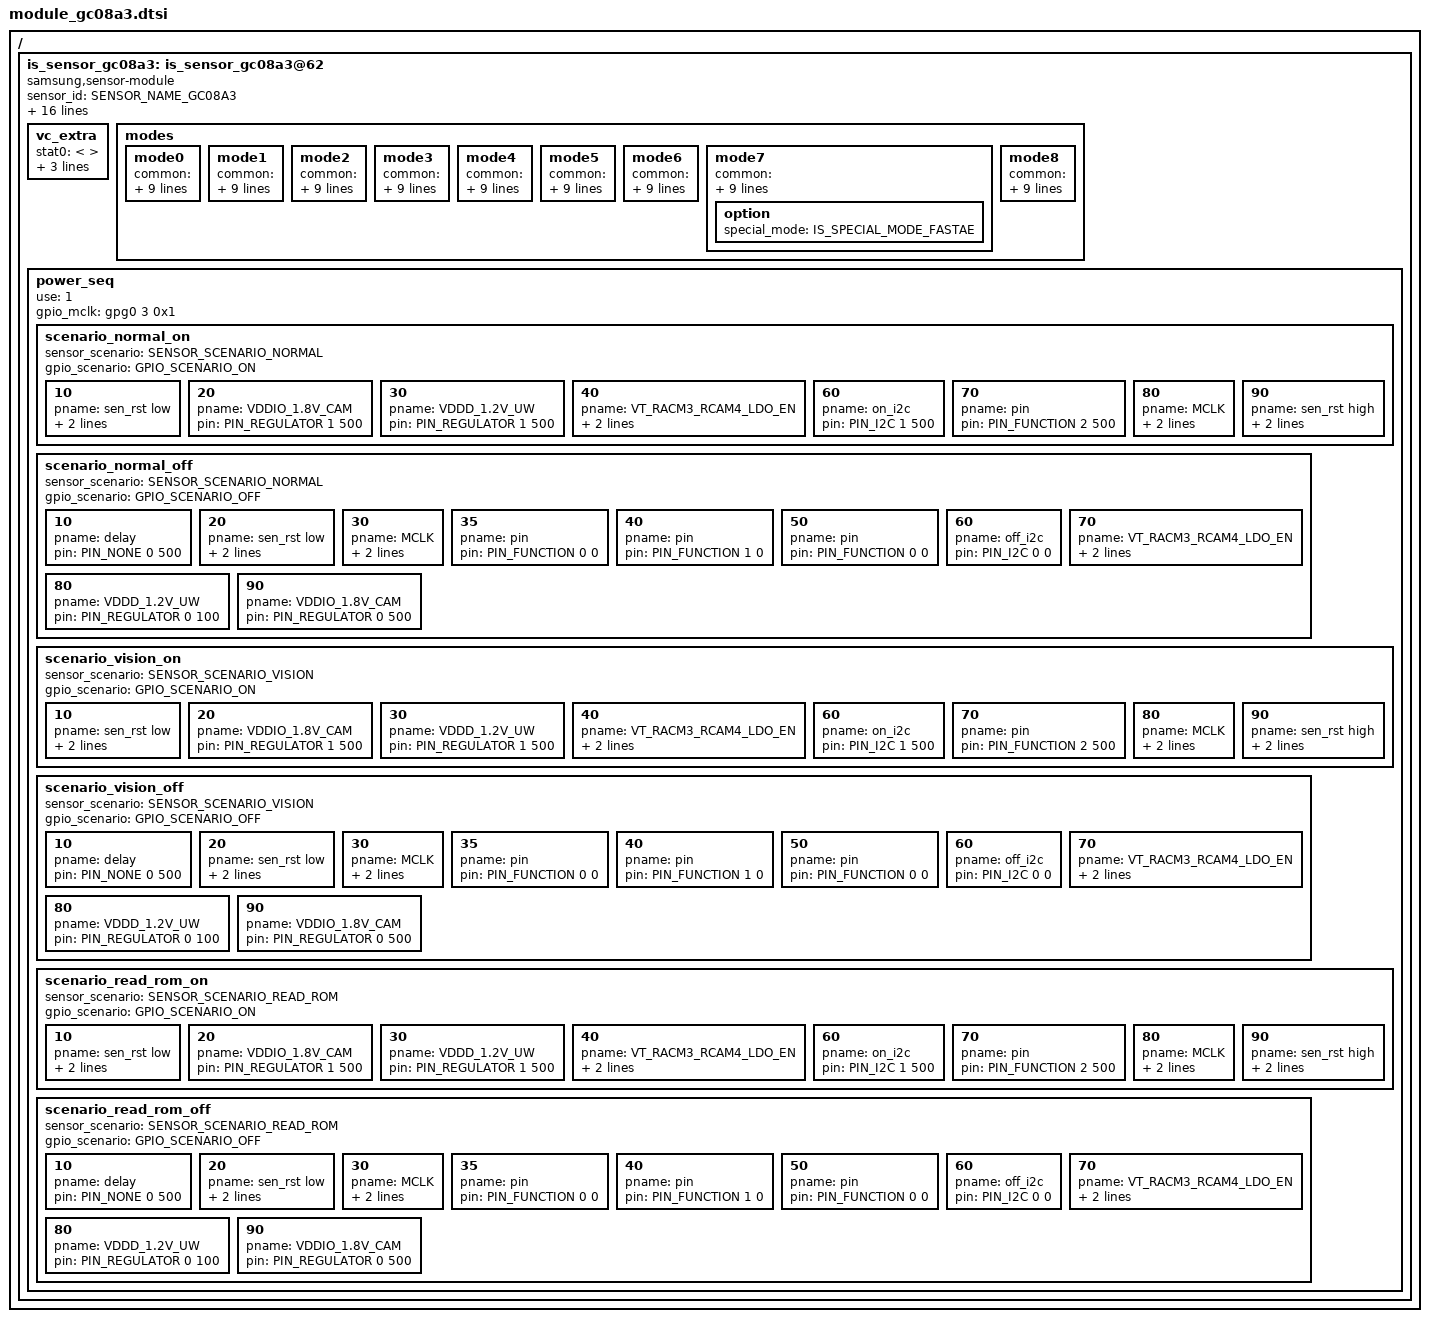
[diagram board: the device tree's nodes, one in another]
/*
 * SAMSUNG EXYNOSxxxx board camera device tree source
 *
 * Copyright (c) 2021 Samsung Electronics Co., Ltd.
 *        http://www.samsung.com
 *
 * This program is free software; you can redistribute it and/or modify
 * it under the terms of the GNU General Public License version 2 as
 * published by the Free Software Foundation.
 */

#include <dt-bindings/camera/exynos_is_dt.h>

/ {
	fragment@camera {
		target-path = "/";
		__overlay__ {
			is_sensor_gc08a3: is_sensor_gc08a3@62 {
				compatible = "samsung,sensor-module";

				/* common */
				sensor_id = <SENSOR_NAME_GC08A3>;
				active_width = <3264>;
				active_height = <2448>;
				margin_left = <0>;
				margin_right = <0>;
				margin_top = <0>;
				margin_bottom = <0>;
				max_framerate = <60>;
				bitwidth = <10>;
				use_retention_mode = <SENSOR_RETENTION_UNSUPPORTED>;
				sensor_maker = "GALAXYCORE";
				sensor_name = "GC08A3";
				setfile_name = "setfile_gc08a3.bin";

				status = "okay";

				/* vendor */
				rom_type = <3>; /* ROM_TYPE_OTPROM */
				rom_id = <2>;
				rom_cal_index = <0>;

				vc_extra {
					/* ex) statX = <stat_type, sensor_mode, max_width, max_height, max_element> */
					stat0 = </* not avaliable */>;	/* VC_BUF_DATA_TYPE_SENSOR_STAT1 */
					stat1 = </* not avaliable */>;	/* VC_BUF_DATA_TYPE_GENERAL_STAT1 */
					stat2 = </* not avaliable */>;	/* VC_BUF_DATA_TYPE_SENSOR_STAT2 */
					stat3 = </* not avaliable */>;	/* VC_BUF_DATA_TYPE_GENERAL_STAT2 */
				};

				/* sensor modes */
				modes {
						/* common = <width, height, fps, settle, mode, lane, speed, interleave, lrte, pd_mode> */
						/* vcX = <map, hwformat, width, height, hwformat, type, width, height> */

					/* 0 : 3264x2448@30fps 4:3 */
					mode0 {
						common = <3264 2448 30 0 0 CSI_DATA_LANES_4 670 CSI_MODE_VC_ONLY LRTE_DISABLE PD_NONE EX_NONE>;
						vc0 = </* in */ 0 HW_FORMAT_RAW10 3264 2448	/* out */ HW_FORMAT_RAW10 VC_NOTHING 3264 2448>;
						vc1 = </* in */ 1 HW_FORMAT_UNKNOWN 0 0		/* out */ HW_FORMAT_UNKNOWN VC_NOTHING 0 0>;
						vc2 = </* in */ 2 HW_FORMAT_UNKNOWN 0 0		/* out */ HW_FORMAT_UNKNOWN VC_NOTHING 0 0>;
						vc3 = </* in */ 3 HW_FORMAT_UNKNOWN 0 0		/* out */ HW_FORMAT_UNKNOWN VC_NOTHING 0 0>;
					};
					/* 1 : 3264x1836@30fps 16:9 */
					mode1 {
						common = <3264 1836 30 0 1 CSI_DATA_LANES_4 670 CSI_MODE_VC_ONLY LRTE_DISABLE PD_NONE EX_NONE>;
						vc0 = </* in */ 0 HW_FORMAT_RAW10 3264 1836	/* out */ HW_FORMAT_RAW10 VC_NOTHING 3264 1836>;
						vc1 = </* in */ 1 HW_FORMAT_UNKNOWN 0 0		/* out */ HW_FORMAT_UNKNOWN VC_NOTHING 0 0>;
						vc2 = </* in */ 2 HW_FORMAT_UNKNOWN 0 0		/* out */ HW_FORMAT_UNKNOWN VC_NOTHING 0 0>;
						vc3 = </* in */ 3 HW_FORMAT_UNKNOWN 0 0		/* out */ HW_FORMAT_UNKNOWN VC_NOTHING 0 0>;
					};
					/* 2 : 2880x1980@30fps 16:9 */
					mode2 {
						common = <2880 1980 30 0 2 CSI_DATA_LANES_4 670 CSI_MODE_VC_ONLY LRTE_DISABLE PD_NONE EX_NONE>;
						vc0 = </* in */ 0 HW_FORMAT_RAW10 2880 1980	/* out */ HW_FORMAT_RAW10 VC_NOTHING 2880 1980>;
						vc1 = </* in */ 1 HW_FORMAT_UNKNOWN 0 0		/* out */ HW_FORMAT_UNKNOWN VC_NOTHING 0 0>;
						vc2 = </* in */ 2 HW_FORMAT_UNKNOWN 0 0		/* out */ HW_FORMAT_UNKNOWN VC_NOTHING 0 0>;
						vc3 = </* in */ 3 HW_FORMAT_UNKNOWN 0 0		/* out */ HW_FORMAT_UNKNOWN VC_NOTHING 0 0>;
					};
					/* 3 : 2640x1980@30fps 4:3 */
					mode3 {
						common = <2640 1980 30 0 3 CSI_DATA_LANES_4 670 CSI_MODE_VC_ONLY LRTE_DISABLE PD_NONE EX_NONE>;
						vc0 = </* in */ 0 HW_FORMAT_RAW10 2640 1980	/* out */ HW_FORMAT_RAW10 VC_NOTHING 2640 1980>;
						vc1 = </* in */ 1 HW_FORMAT_UNKNOWN 0 0		/* out */ HW_FORMAT_UNKNOWN VC_NOTHING 0 0>;
						vc2 = </* in */ 2 HW_FORMAT_UNKNOWN 0 0		/* out */ HW_FORMAT_UNKNOWN VC_NOTHING 0 0>;
						vc3 = </* in */ 3 HW_FORMAT_UNKNOWN 0 0		/* out */ HW_FORMAT_UNKNOWN VC_NOTHING 0 0>;
					};
					/* 4 : 2640x1488@30fps 4:3 */
					mode4 {
						common = <2640 1488 30 0 4 CSI_DATA_LANES_4 670 CSI_MODE_VC_ONLY LRTE_DISABLE PD_NONE EX_NONE>;
						vc0 = </* in */ 0 HW_FORMAT_RAW10 2640 1488	/* out */ HW_FORMAT_RAW10 VC_NOTHING 2640 1488>;
						vc1 = </* in */ 1 HW_FORMAT_UNKNOWN 0 0		/* out */ HW_FORMAT_UNKNOWN VC_NOTHING 0 0>;
						vc2 = </* in */ 2 HW_FORMAT_UNKNOWN 0 0		/* out */ HW_FORMAT_UNKNOWN VC_NOTHING 0 0>;
						vc3 = </* in */ 3 HW_FORMAT_UNKNOWN 0 0		/* out */ HW_FORMAT_UNKNOWN VC_NOTHING 0 0>;
					};
					/* 5 : 1632x1224@30fps 4:3 */
					mode5 {
						common = <1632 1224 30 0 5 CSI_DATA_LANES_4 345 CSI_MODE_VC_ONLY LRTE_DISABLE PD_NONE EX_NONE>;
						vc0 = </* in */ 0 HW_FORMAT_RAW10 1632 1224	/* out */ HW_FORMAT_RAW10 VC_NOTHING 1632 1224>;
						vc1 = </* in */ 1 HW_FORMAT_UNKNOWN 0 0		/* out */ HW_FORMAT_UNKNOWN VC_NOTHING 0 0>;
						vc2 = </* in */ 2 HW_FORMAT_UNKNOWN 0 0		/* out */ HW_FORMAT_UNKNOWN VC_NOTHING 0 0>;
						vc3 = </* in */ 3 HW_FORMAT_UNKNOWN 0 0		/* out */ HW_FORMAT_UNKNOWN VC_NOTHING 0 0>;
					};
					/* 6 : 1632x916@30fps 4:3 */
					mode6 {
						common = <1632 916 30 0 6 CSI_DATA_LANES_4 345 CSI_MODE_VC_ONLY LRTE_DISABLE PD_NONE EX_NONE>;
						vc0 = </* in */ 0 HW_FORMAT_RAW10 1632 916	/* out */ HW_FORMAT_RAW10 VC_NOTHING 1632 916>;
						vc1 = </* in */ 1 HW_FORMAT_UNKNOWN 0 0		/* out */ HW_FORMAT_UNKNOWN VC_NOTHING 0 0>;
						vc2 = </* in */ 2 HW_FORMAT_UNKNOWN 0 0		/* out */ HW_FORMAT_UNKNOWN VC_NOTHING 0 0>;
						vc3 = </* in */ 3 HW_FORMAT_UNKNOWN 0 0		/* out */ HW_FORMAT_UNKNOWN VC_NOTHING 0 0>;
					};
					/* 7 : 1632x1224@60fps 4:3 */
					mode7 {
						common = <1632 1224 60 0 7 CSI_DATA_LANES_4 345 CSI_MODE_VC_ONLY LRTE_DISABLE PD_NONE EX_NONE>;
						vc0 = </* in */ 0 HW_FORMAT_RAW10 1632 1224	/* out */ HW_FORMAT_RAW10 VC_NOTHING 1632 1224>;
						vc1 = </* in */ 1 HW_FORMAT_UNKNOWN 0 0		/* out */ HW_FORMAT_UNKNOWN VC_NOTHING 0 0>;
						vc2 = </* in */ 2 HW_FORMAT_UNKNOWN 0 0		/* out */ HW_FORMAT_UNKNOWN VC_NOTHING 0 0>;
						vc3 = </* in */ 3 HW_FORMAT_UNKNOWN 0 0		/* out */ HW_FORMAT_UNKNOWN VC_NOTHING 0 0>;
						option { special_mode = <IS_SPECIAL_MODE_FASTAE>; };
					};
					/* 8 : 1280x720@90fps 4:3 */
					mode8 {
						common = <1280 720 90 0 8 CSI_DATA_LANES_4 280 CSI_MODE_VC_ONLY LRTE_DISABLE PD_NONE EX_NONE>;
						vc0 = </* in */ 0 HW_FORMAT_RAW10 1280 720	/* out */ HW_FORMAT_RAW10 VC_NOTHING 1280 720>;
						vc1 = </* in */ 1 HW_FORMAT_UNKNOWN 0 0		/* out */ HW_FORMAT_UNKNOWN VC_NOTHING 0 0>;
						vc2 = </* in */ 2 HW_FORMAT_UNKNOWN 0 0		/* out */ HW_FORMAT_UNKNOWN VC_NOTHING 0 0>;
						vc3 = </* in */ 3 HW_FORMAT_UNKNOWN 0 0		/* out */ HW_FORMAT_UNKNOWN VC_NOTHING 0 0>;
					};
				};

				power_seq {
					use = <1>;
					gpio_mclk = <&gpg0 3 0x1>;

					scenario_normal_on {
						sensor_scenario = <SENSOR_SCENARIO_NORMAL>;
						gpio_scenario = <GPIO_SCENARIO_ON>;

						/* A start node number should be over the 10 for reserved number 0~9. */
						/* pname = "name";	pin = <act value dealy voltage>;		gpio = <gpx# # 0x1>;	*/
						10 { pname = "sen_rst low"; pin = <PIN_OUTPUT 0 500>; gpio = <&gpm3 0 0x1>; };
						20 { pname = "VDDIO_1.8V_CAM"; pin = <PIN_REGULATOR 1 500>; };
						30 { pname = "VDDD_1.2V_UW"; pin = <PIN_REGULATOR 1 500>; };
						40 { pname = "VT_RACM3_RCAM4_LDO_EN"; pin = <PIN_OUTPUT 1 1500>; gpio = <&gpm12 0 0x1>; };
						60 { pname = "on_i2c"; pin = <PIN_I2C 1 500>; };
						70 { pname = "pin"; pin = <PIN_FUNCTION 2 500>; };
						80 { pname = "MCLK"; pin = <PIN_MCLK 1 1000>; gpio = <&gpg0 3 0x1>; };
						90 { pname = "sen_rst high"; pin = <PIN_OUTPUT 1 2000>; gpio = <&gpm3 0 0x1>; };
					};

					scenario_normal_off {
						sensor_scenario = <SENSOR_SCENARIO_NORMAL>;
						gpio_scenario = <GPIO_SCENARIO_OFF>;

						/* A start node number should be over the 10 for reserved number 0~9. */
						/* pname = "name";		pin = <act value dealy voltage>;	gpio = <gpx# # 0x1>;	*/
						10 { pname = "delay"; pin = <PIN_NONE 0 500>; };
						20 { pname = "sen_rst low"; pin = <PIN_OUTPUT 0 1000>; gpio = <&gpm3 0 0x1>; };
						30 { pname = "MCLK"; pin = <PIN_MCLK 0 500>; gpio = <&gpg0 3 0x1>; };
						35 { pname = "pin"; pin = <PIN_FUNCTION 0 0>; };
						40 { pname = "pin"; pin = <PIN_FUNCTION 1 0>; };
						50 { pname = "pin"; pin = <PIN_FUNCTION 0 0>; };
						60 { pname = "off_i2c"; pin = <PIN_I2C 0 0>; };
						70 { pname = "VT_RACM3_RCAM4_LDO_EN"; pin = <PIN_OUTPUT 0 1000>; gpio = <&gpm12 0 0x1>; };
						80 { pname = "VDDD_1.2V_UW"; pin = <PIN_REGULATOR 0 100>; };
						90 { pname = "VDDIO_1.8V_CAM"; pin = <PIN_REGULATOR 0 500>; };
					};

					scenario_vision_on {
						sensor_scenario = <SENSOR_SCENARIO_VISION>;
						gpio_scenario = <GPIO_SCENARIO_ON>;

						/* A start node number should be over the 10 for reserved number 0~9. */
						/* pname = "name"; pin = <act value dealy voltage>; gpio = <gpx# # 0x1>; */
						10 { pname = "sen_rst low"; pin = <PIN_OUTPUT 0 500>; gpio = <&gpm3 0 0x1>; };
						20 { pname = "VDDIO_1.8V_CAM"; pin = <PIN_REGULATOR 1 500>; };
						30 { pname = "VDDD_1.2V_UW"; pin = <PIN_REGULATOR 1 500>; };
						40 { pname = "VT_RACM3_RCAM4_LDO_EN"; pin = <PIN_OUTPUT 1 1500>; gpio = <&gpm12 0 0x1>; };
						60 { pname = "on_i2c"; pin = <PIN_I2C 1 500>; };
						70 { pname = "pin"; pin = <PIN_FUNCTION 2 500>; };
						80 { pname = "MCLK"; pin = <PIN_MCLK 1 1000>; gpio = <&gpg0 3 0x1>; };
						90 { pname = "sen_rst high"; pin = <PIN_OUTPUT 1 2000>; gpio = <&gpm3 0 0x1>; };
					};

					scenario_vision_off {
						sensor_scenario = <SENSOR_SCENARIO_VISION>;
						gpio_scenario = <GPIO_SCENARIO_OFF>;

						/* A start node number should be over the 10 for reserved number 0~9. */
						/* pname = "name"; pin = <act value dealy voltage>; gpio = <gpx# # 0x1>; */
						10 { pname = "delay"; pin = <PIN_NONE 0 500>; };
						20 { pname = "sen_rst low"; pin = <PIN_OUTPUT 0 1000>; gpio = <&gpm3 0 0x1>; };
						30 { pname = "MCLK"; pin = <PIN_MCLK 0 500>; gpio = <&gpg0 3 0x1>; };
						35 { pname = "pin"; pin = <PIN_FUNCTION 0 0>; };
						40 { pname = "pin"; pin = <PIN_FUNCTION 1 0>; };
						50 { pname = "pin"; pin = <PIN_FUNCTION 0 0>; };
						60 { pname = "off_i2c"; pin = <PIN_I2C 0 0>; };
						70 { pname = "VT_RACM3_RCAM4_LDO_EN"; pin = <PIN_OUTPUT 0 1000>; gpio = <&gpm12 0 0x1>; };
						80 { pname = "VDDD_1.2V_UW"; pin = <PIN_REGULATOR 0 100>; };
						90 { pname = "VDDIO_1.8V_CAM"; pin = <PIN_REGULATOR 0 500>; };
					};

					scenario_read_rom_on {
						sensor_scenario = <SENSOR_SCENARIO_READ_ROM>;
						gpio_scenario = <GPIO_SCENARIO_ON>;

						/* A start node number should be over the 10 for reserved number 0~9. */
						/* pname = "name";	pin = <act value dealy voltage>; gpio = <gpx# # 0x1>; */
						10 { pname = "sen_rst low"; pin = <PIN_OUTPUT 0 500>; gpio = <&gpm3 0 0x1>; };
						20 { pname = "VDDIO_1.8V_CAM"; pin = <PIN_REGULATOR 1 500>; };
						30 { pname = "VDDD_1.2V_UW"; pin = <PIN_REGULATOR 1 500>; };
						40 { pname = "VT_RACM3_RCAM4_LDO_EN"; pin = <PIN_OUTPUT 1 3000>; gpio = <&gpm12 0 0x1>; };
						60 { pname = "on_i2c"; pin = <PIN_I2C 1 500>; };
						70 { pname = "pin"; pin = <PIN_FUNCTION 2 500>; };
						80 { pname = "MCLK"; pin = <PIN_MCLK 1 1000>; gpio = <&gpg0 3 0x1>; };
						90 { pname = "sen_rst high"; pin = <PIN_OUTPUT 1 10000>; gpio = <&gpm3 0 0x1>; };
					};

					scenario_read_rom_off {
						sensor_scenario = <SENSOR_SCENARIO_READ_ROM>;
						gpio_scenario = <GPIO_SCENARIO_OFF>;

						/* A start node number should be over the 10 for reserved number 0~9. */
						/* pname = "name"; pin = <act value dealy voltage>; gpio = <gpx# # 0x1>; */
						10 { pname = "delay"; pin = <PIN_NONE 0 500>; };
						20 { pname = "sen_rst low"; pin = <PIN_OUTPUT 0 1000>; gpio = <&gpm3 0 0x1>; };
						30 { pname = "MCLK"; pin = <PIN_MCLK 0 500>; gpio = <&gpg0 3 0x1>; };
						35 { pname = "pin"; pin = <PIN_FUNCTION 0 0>; };
						40 { pname = "pin"; pin = <PIN_FUNCTION 1 0>; };
						50 { pname = "pin"; pin = <PIN_FUNCTION 0 0>; };
						60 { pname = "off_i2c"; pin = <PIN_I2C 0 0>; };
						70 { pname = "VT_RACM3_RCAM4_LDO_EN"; pin = <PIN_OUTPUT 0 1000>; gpio = <&gpm12 0 0x1>; };
						80 { pname = "VDDD_1.2V_UW"; pin = <PIN_REGULATOR 0 100>; };
						90 { pname = "VDDIO_1.8V_CAM"; pin = <PIN_REGULATOR 0 500>; };
					};
				}; /* power_seq */
			}; /* is_sensor_gc08a3 */
		}; /* end of __overlay__ */
	}; /* end of fragment */
}; /* end of root */
